VERSION ""

NS_ :

BS_:

BU_: BuckConvertor

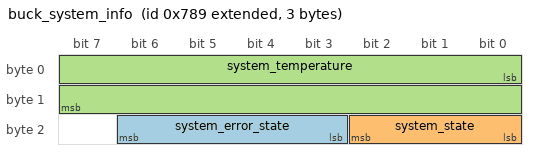
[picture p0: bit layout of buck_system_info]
BO_ 2147485577 buck_system_info: 3 BuckConvertor
 SG_ system_error_state : 19|4@1+ (1,0) [0|15] "" Vector__XXX
 SG_ system_state : 16|3@1+ (1,0) [0|4] "" Vector__XXX
 SG_ system_temperature : 0|16@1+ (0.1,0) [0|70] "Degree" Vector__XXX

BO_ 2147484758 buck_current_info: 8 BuckConvertor
 SG_ SupplyCurrent : 32|32@1- (1,0) [0|20] "A" Vector__XXX
 SG_ LoadCurrent : 0|32@1- (1,0) [0|20] "A" Vector__XXX

BO_ 2147483939 buck_voltage_info: 8 BuckConvertor
 SG_ SupplyVoltage : 32|32@1- (1,0) [0|100] "V" Vector__XXX
 SG_ LoadVoltage : 0|32@1- (1,0) [0|48] "V" Vector__XXX

BA_DEF_  "BusType" STRING ;
BA_DEF_DEF_  "BusType" "CAN";
SIG_VALTYPE_ 2147484758 SupplyCurrent : 1;
SIG_VALTYPE_ 2147484758 LoadCurrent : 1;
SIG_VALTYPE_ 2147483939 SupplyVoltage : 1;
SIG_VALTYPE_ 2147483939 LoadVoltage : 1;
